# WKUP_CTRL_MMR1_CFG0 register map
Vendor: Texas Instruments
Registers are 32-bit, read-write, reset 0x0 unless marked. A register's access mark holds for its fields unless they carry their own. Offsets are as the file gives them; [hi:lo] are bit positions; {n}, {i} and the like mark numbered series.

## WKUP_CTRL_MMR1_CFG0 (part 2 of 2)
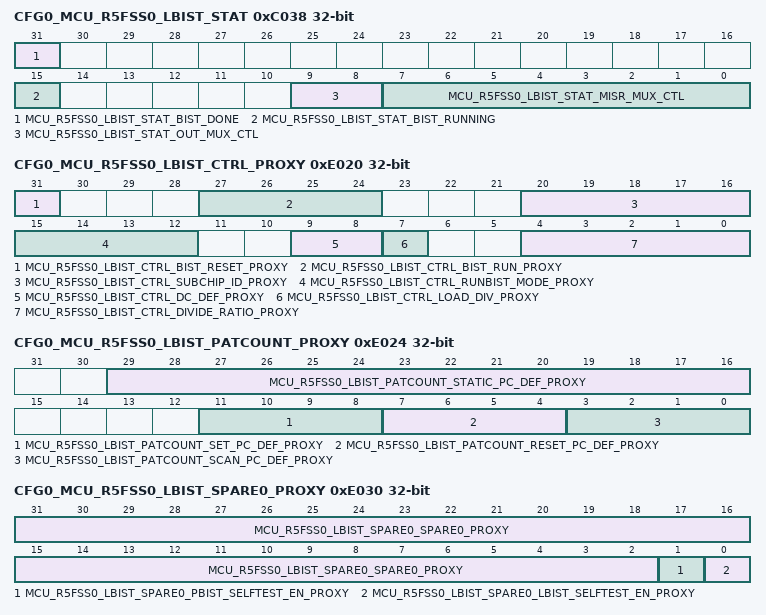
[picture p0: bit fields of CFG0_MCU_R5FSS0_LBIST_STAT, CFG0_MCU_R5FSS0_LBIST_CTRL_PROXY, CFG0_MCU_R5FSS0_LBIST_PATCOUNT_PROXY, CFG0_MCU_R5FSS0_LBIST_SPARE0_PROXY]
0xC038 CFG0_MCU_R5FSS0_LBIST_STAT access per field
  [31] MCU_R5FSS0_LBIST_STAT_BIST_DONE ro — LBIST is done
  [15] MCU_R5FSS0_LBIST_STAT_BIST_RUNNING ro — LBIST is running
  [9:8] MCU_R5FSS0_LBIST_STAT_OUT_MUX_CTL rw — Selects source of LBIST output 00 - LBIST IP PID value 01 - LBIST CTRL ID value 1x - MISR value
  [7:0] MCU_R5FSS0_LBIST_STAT_MISR_MUX_CTL rw — Selects block of 32 MISR bits to read. A value of 0 selects a compacted 32-bit version of the full MISR. A value of 1-32 select a 32-bit segment of the MISR.
0xC03C CFG0_MCU_R5FSS0_LBIST_MISR ro
  [31:0] MCU_R5FSS0_LBIST_MISR_MISR_RESULT — 32-bits of MISR value selected by misr_mux_ctl
0xD100 CFG0_CLAIMREG_P3_R0_READONLY ro
  [31:0] CLAIMREG_P3_R0_READONLY — Claim bits for Partition 3
0xE020 CFG0_MCU_R5FSS0_LBIST_CTRL_PROXY
  [31] MCU_R5FSS0_LBIST_CTRL_BIST_RESET_PROXY — This bitfield is not used.
  [27:24] MCU_R5FSS0_LBIST_CTRL_BIST_RUN_PROXY — This bitfield is not used.
  [20:16] MCU_R5FSS0_LBIST_CTRL_SUBCHIP_ID_PROXY — Specifies which sub-chip is to be tested
  [15:12] MCU_R5FSS0_LBIST_CTRL_RUNBIST_MODE_PROXY — Runbist mode activate if all bits are 1
  [9:8] MCU_R5FSS0_LBIST_CTRL_DC_DEF_PROXY — Clock delay after scan_activate switching
  [7] MCU_R5FSS0_LBIST_CTRL_LOAD_DIV_PROXY — Loads LBIST clock divide ratio on transition from 0 to 1
  [4:0] MCU_R5FSS0_LBIST_CTRL_DIVIDE_RATIO_PROXY — LBIST clock divide ratio
0xE024 CFG0_MCU_R5FSS0_LBIST_PATCOUNT_PROXY
  [29:16] MCU_R5FSS0_LBIST_PATCOUNT_STATIC_PC_DEF_PROXY — Number of stuck-at patterns to run
  [11:8] MCU_R5FSS0_LBIST_PATCOUNT_SET_PC_DEF_PROXY — Number of set patterns to run
  [7:4] MCU_R5FSS0_LBIST_PATCOUNT_RESET_PC_DEF_PROXY — Number of reset patterns to run
  [3:0] MCU_R5FSS0_LBIST_PATCOUNT_SCAN_PC_DEF_PROXY — Number of chain test patterns to run
0xE028 CFG0_MCU_R5FSS0_LBIST_SEED0_PROXY
  [31:0] MCU_R5FSS0_LBIST_SEED0_PRPG_DEF_PROXY — Initial seed for PRPG (bits 31:0)
0xE02C CFG0_MCU_R5FSS0_LBIST_SEED1_PROXY
  [20:0] MCU_R5FSS0_LBIST_SEED1_PRPG_DEF_PROXY — Initial seed for PRPG (bits 52:32)
0xE030 CFG0_MCU_R5FSS0_LBIST_SPARE0_PROXY
  [31:2] MCU_R5FSS0_LBIST_SPARE0_SPARE0_PROXY — LBIST spare bits
  [1] MCU_R5FSS0_LBIST_SPARE0_PBIST_SELFTEST_EN_PROXY — PBIST isolation control
  [0] MCU_R5FSS0_LBIST_SPARE0_LBIST_SELFTEST_EN_PROXY — LBIST isolation control
0xE034 CFG0_MCU_R5FSS0_LBIST_SPARE1_PROXY
  [31:0] MCU_R5FSS0_LBIST_SPARE1_SPARE1_PROXY — LBIST spare bits
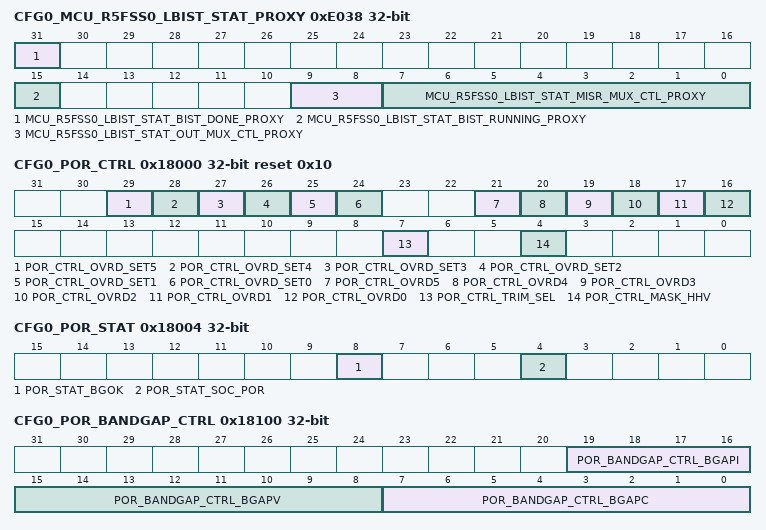
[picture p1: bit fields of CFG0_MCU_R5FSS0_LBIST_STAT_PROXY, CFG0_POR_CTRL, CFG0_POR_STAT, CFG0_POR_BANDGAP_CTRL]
0xE038 CFG0_MCU_R5FSS0_LBIST_STAT_PROXY access per field
  [31] MCU_R5FSS0_LBIST_STAT_BIST_DONE_PROXY ro — LBIST is done
  [15] MCU_R5FSS0_LBIST_STAT_BIST_RUNNING_PROXY ro — LBIST is running
  [9:8] MCU_R5FSS0_LBIST_STAT_OUT_MUX_CTL_PROXY rw — Selects source of LBIST output 00 - LBIST IP PID value 01 - LBIST CTRL ID value 1x - MISR value
  [7:0] MCU_R5FSS0_LBIST_STAT_MISR_MUX_CTL_PROXY rw — Selects block of 32 MISR bits to read. A value of 0 selects a compacted 32-bit version of the full MISR. A value of 1-32 select a 32-bit segment of the MISR.
0xE03C CFG0_MCU_R5FSS0_LBIST_MISR_PROXY ro
  [31:0] MCU_R5FSS0_LBIST_MISR_MISR_RESULT_PROXY — 32-bits of MISR value selected by misr_mux_ctl
0xF100 CFG0_CLAIMREG_P3_R0
  [31:0] CLAIMREG_P3_R0 — Claim bits for Partition 3
{0x11100+4i} CFG0_CLAIMREG_P4_R{i}_READONLY ro (i=0..19)
  [31:0] CLAIMREG_P4_R{i}_READONLY — Claim bits for Partition 4
{0x13100+4i} CFG0_CLAIMREG_P4_R{i} (i=0..19)
  [31:0] CLAIMREG_P4_R{i} — Claim bits for Partition 4
0x18000 CFG0_POR_CTRL reset 0x10
  [29] POR_CTRL_OVRD_SET5 — Reserved override set
  [28] POR_CTRL_OVRD_SET4 — POKLVB override set
  [27] POR_CTRL_OVRD_SET3 — POKLVA override set
  [26] POR_CTRL_OVRD_SET2 — POKHV override set
  [25] POR_CTRL_OVRD_SET1 — BGOK override set
  [24] POR_CTRL_OVRD_SET0 — PORHV override set
  [21] POR_CTRL_OVRD5 — Reserved override activate
  [20] POR_CTRL_OVRD4 — POKLVB override activate
  [19] POR_CTRL_OVRD3 — POKLVA override activate
  [18] POR_CTRL_OVRD2 — POKHV override activate
  [17] POR_CTRL_OVRD1 — BGOK override activate
  [16] POR_CTRL_OVRD0 — PORHV override activate
  [7] POR_CTRL_TRIM_SEL — POR Trim Select 0 - Trim selections for Bandgap and POKs come from HHV defaults 1 - Trim selections for Bandgap and POKs come from POR_BANDGAP_CTRL and POR_POKxxx_CTRL registers
  [4] POR_CTRL_MASK_HHV — Mask HHV/SOC_PORz outputs when applying new trim values
0x18004 CFG0_POR_STAT ro
  [8] POR_STAT_BGOK — Bandgap OK status
  [4] POR_STAT_SOC_POR — POR module status 0 - Module is in functional mode 1 - Module is in reset mode
0x18100 CFG0_POR_BANDGAP_CTRL
  [19:16] POR_BANDGAP_CTRL_BGAPI — Bandgap output current trim bits
  [15:8] POR_BANDGAP_CTRL_BGAPV — Bandgap output voltage magnitude trim bits
  [7:0] POR_BANDGAP_CTRL_BGAPC — Bandgap slope trim bits. Bit7 is used to calculate the offset
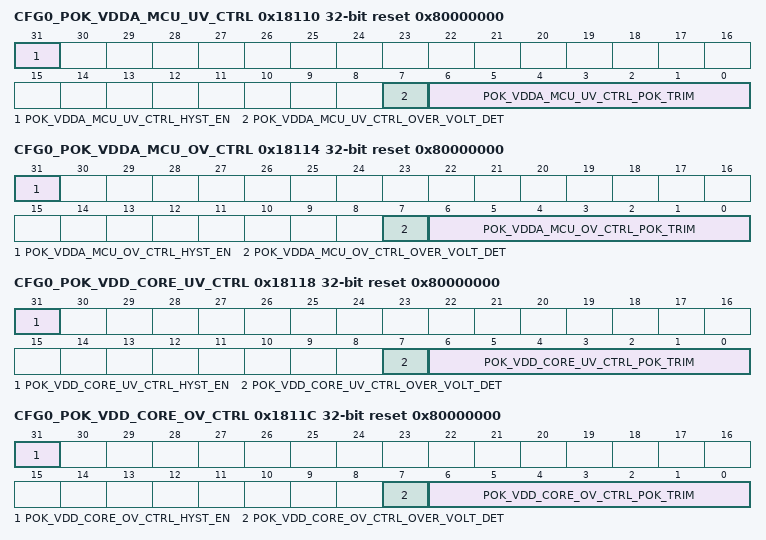
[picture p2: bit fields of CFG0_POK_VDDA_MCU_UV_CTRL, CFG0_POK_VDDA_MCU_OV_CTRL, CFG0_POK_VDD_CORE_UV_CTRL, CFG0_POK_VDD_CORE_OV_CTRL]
0x18110 CFG0_POK_VDDA_MCU_UV_CTRL reset 0x80000000
  [31] POK_VDDA_MCU_UV_CTRL_HYST_EN — Activate POK hysteresis
  [7] POK_VDDA_MCU_UV_CTRL_OVER_VOLT_DET — Over / under voltage detection mode 0 - Under voltage detection 1 - Over voltage detection
  [6:0] POK_VDDA_MCU_UV_CTRL_POK_TRIM — POK Trim Bits
0x18114 CFG0_POK_VDDA_MCU_OV_CTRL reset 0x80000000
  [31] POK_VDDA_MCU_OV_CTRL_HYST_EN — Activate POK hysteresis
  [7] POK_VDDA_MCU_OV_CTRL_OVER_VOLT_DET — Over / under voltage detection mode 0 - Under voltage detection 1 - Over voltage detection
  [6:0] POK_VDDA_MCU_OV_CTRL_POK_TRIM — POK Trim Bits
0x18118 CFG0_POK_VDD_CORE_UV_CTRL reset 0x80000000
  [31] POK_VDD_CORE_UV_CTRL_HYST_EN — Activate POK hysteresis
  [7] POK_VDD_CORE_UV_CTRL_OVER_VOLT_DET — Over / under voltage detection mode 0 - Under voltage detection 1 - Over voltage detection
  [6:0] POK_VDD_CORE_UV_CTRL_POK_TRIM — POK Trim Bits
0x1811C CFG0_POK_VDD_CORE_OV_CTRL reset 0x80000000
  [31] POK_VDD_CORE_OV_CTRL_HYST_EN — Activate POK hysteresis
  [7] POK_VDD_CORE_OV_CTRL_OVER_VOLT_DET — Over / under voltage detection mode 0 - Under voltage detection 1 - Over voltage detection
  [6:0] POK_VDD_CORE_OV_CTRL_POK_TRIM — POK Trim Bits
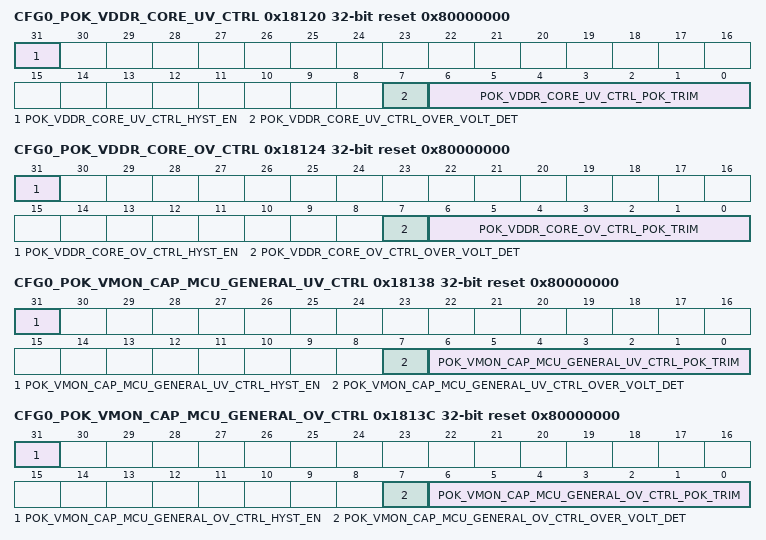
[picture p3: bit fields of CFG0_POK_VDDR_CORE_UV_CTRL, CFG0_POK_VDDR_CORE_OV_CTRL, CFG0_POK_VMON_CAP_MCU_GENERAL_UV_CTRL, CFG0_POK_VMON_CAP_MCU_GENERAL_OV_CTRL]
0x18120 CFG0_POK_VDDR_CORE_UV_CTRL reset 0x80000000
  [31] POK_VDDR_CORE_UV_CTRL_HYST_EN — Activate POK hysteresis
  [7] POK_VDDR_CORE_UV_CTRL_OVER_VOLT_DET — Over / under voltage detection mode 0 - Under voltage detection 1 - Over voltage detection
  [6:0] POK_VDDR_CORE_UV_CTRL_POK_TRIM — POK Trim Bits
0x18124 CFG0_POK_VDDR_CORE_OV_CTRL reset 0x80000000
  [31] POK_VDDR_CORE_OV_CTRL_HYST_EN — Activate POK hysteresis
  [7] POK_VDDR_CORE_OV_CTRL_OVER_VOLT_DET — Over / under voltage detection mode 0 - Under voltage detection 1 - Over voltage detection
  [6:0] POK_VDDR_CORE_OV_CTRL_POK_TRIM — POK Trim Bits
0x18138 CFG0_POK_VMON_CAP_MCU_GENERAL_UV_CTRL reset 0x80000000
  [31] POK_VMON_CAP_MCU_GENERAL_UV_CTRL_HYST_EN — Activate POK hysteresis
  [7] POK_VMON_CAP_MCU_GENERAL_UV_CTRL_OVER_VOLT_DET — Over / under voltage detection mode 0 - Under voltage detection 1 - Over voltage detection
  [6:0] POK_VMON_CAP_MCU_GENERAL_UV_CTRL_POK_TRIM — POK Trim Bits
0x1813C CFG0_POK_VMON_CAP_MCU_GENERAL_OV_CTRL reset 0x80000000
  [31] POK_VMON_CAP_MCU_GENERAL_OV_CTRL_HYST_EN — Activate POK hysteresis
  [7] POK_VMON_CAP_MCU_GENERAL_OV_CTRL_OVER_VOLT_DET — Over / under voltage detection mode 0 - Under voltage detection 1 - Over voltage detection
  [6:0] POK_VMON_CAP_MCU_GENERAL_OV_CTRL_POK_TRIM — POK Trim Bits
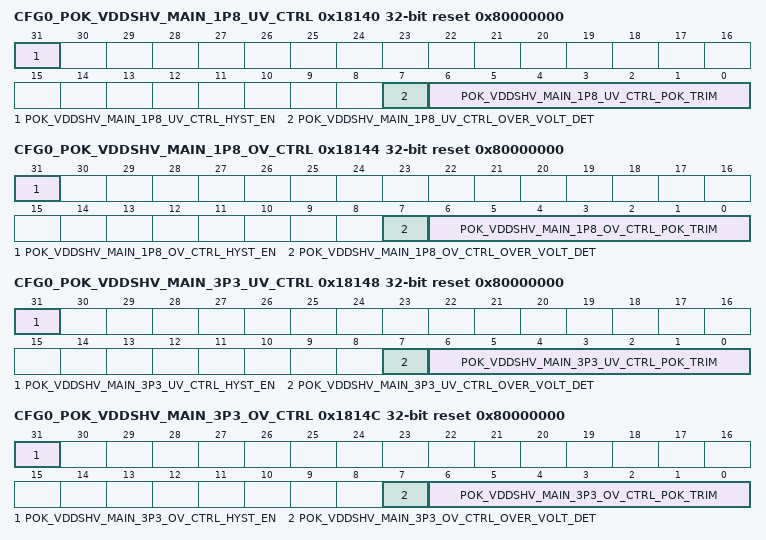
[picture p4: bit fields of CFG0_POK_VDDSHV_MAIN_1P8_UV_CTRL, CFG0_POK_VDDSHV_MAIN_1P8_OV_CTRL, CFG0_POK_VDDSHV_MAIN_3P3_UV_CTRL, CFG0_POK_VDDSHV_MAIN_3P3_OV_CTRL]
0x18140 CFG0_POK_VDDSHV_MAIN_1P8_UV_CTRL reset 0x80000000
  [31] POK_VDDSHV_MAIN_1P8_UV_CTRL_HYST_EN — Activate POK hysteresis
  [7] POK_VDDSHV_MAIN_1P8_UV_CTRL_OVER_VOLT_DET — Over / under voltage detection mode 0 - Under voltage detection 1 - Over voltage detection
  [6:0] POK_VDDSHV_MAIN_1P8_UV_CTRL_POK_TRIM — POK Trim Bits
0x18144 CFG0_POK_VDDSHV_MAIN_1P8_OV_CTRL reset 0x80000000
  [31] POK_VDDSHV_MAIN_1P8_OV_CTRL_HYST_EN — Activate POK hysteresis
  [7] POK_VDDSHV_MAIN_1P8_OV_CTRL_OVER_VOLT_DET — Over / under voltage detection mode 0 - Under voltage detection 1 - Over voltage detection
  [6:0] POK_VDDSHV_MAIN_1P8_OV_CTRL_POK_TRIM — POK Trim Bits
0x18148 CFG0_POK_VDDSHV_MAIN_3P3_UV_CTRL reset 0x80000000
  [31] POK_VDDSHV_MAIN_3P3_UV_CTRL_HYST_EN — Activate POK hysteresis
  [7] POK_VDDSHV_MAIN_3P3_UV_CTRL_OVER_VOLT_DET — Over / under voltage detection mode 0 - Under voltage detection 1 - Over voltage detection
  [6:0] POK_VDDSHV_MAIN_3P3_UV_CTRL_POK_TRIM — POK Trim Bits
0x1814C CFG0_POK_VDDSHV_MAIN_3P3_OV_CTRL reset 0x80000000
  [31] POK_VDDSHV_MAIN_3P3_OV_CTRL_HYST_EN — Activate POK hysteresis
  [7] POK_VDDSHV_MAIN_3P3_OV_CTRL_OVER_VOLT_DET — Over / under voltage detection mode 0 - Under voltage detection 1 - Over voltage detection
  [6:0] POK_VDDSHV_MAIN_3P3_OV_CTRL_POK_TRIM — POK Trim Bits
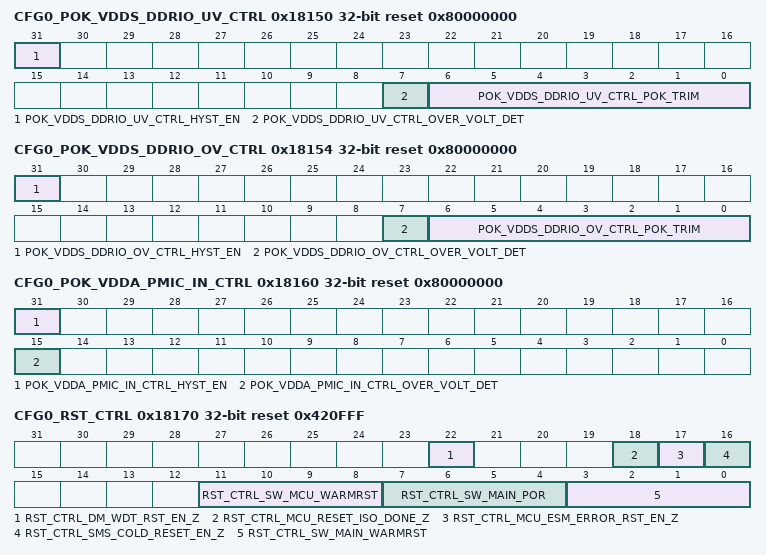
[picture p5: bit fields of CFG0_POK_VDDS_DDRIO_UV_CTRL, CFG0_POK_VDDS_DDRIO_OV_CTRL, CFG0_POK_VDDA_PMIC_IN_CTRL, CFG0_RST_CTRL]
0x18150 CFG0_POK_VDDS_DDRIO_UV_CTRL reset 0x80000000
  [31] POK_VDDS_DDRIO_UV_CTRL_HYST_EN — Activate POK hysteresis
  [7] POK_VDDS_DDRIO_UV_CTRL_OVER_VOLT_DET — Over / under voltage detection mode 0 - Under voltage detection 1 - Over voltage detection
  [6:0] POK_VDDS_DDRIO_UV_CTRL_POK_TRIM — POK Trim Bits
0x18154 CFG0_POK_VDDS_DDRIO_OV_CTRL reset 0x80000000
  [31] POK_VDDS_DDRIO_OV_CTRL_HYST_EN — Activate POK hysteresis
  [7] POK_VDDS_DDRIO_OV_CTRL_OVER_VOLT_DET — Over / under voltage detection mode 0 - Under voltage detection 1 - Over voltage detection
  [6:0] POK_VDDS_DDRIO_OV_CTRL_POK_TRIM — POK Trim Bits
0x18160 CFG0_POK_VDDA_PMIC_IN_CTRL reset 0x80000000
  [31] POK_VDDA_PMIC_IN_CTRL_HYST_EN — Activate POK hysteresis
  [15] POK_VDDA_PMIC_IN_CTRL_OVER_VOLT_DET — Over / under voltage detection mode 0 - Under voltage detection 1 - Over voltage detection
0x18170 CFG0_RST_CTRL reset 0x420FFF
  [22] RST_CTRL_DM_WDT_RST_EN_Z — Deactivate Reset from DM WDT propogating to MCU domain: 0 - Activated 1 - Deactivated
  [18] RST_CTRL_MCU_RESET_ISO_DONE_Z — MCU can set this bit to block warm reset in the main domain which is useful when the MCU may be accessing main domain resources (peripherals, memory..). In this case, the MCU will be notified via an interrupt that there is an outstanding warm reset request for the main domain. Once notified, MCU needs to finish any outstanding operations in has with main domain resources and then clear this bit. After this bit is cleared, the main domain warm reset will unblocked and the warm reset sequence may continue. 0 - Reset of Main Domain is not Blocked by MCU Domain 1 - Reset of Main Domain is Blocked by MCU Domain
  [17] RST_CTRL_MCU_ESM_ERROR_RST_EN_Z — Deactivate Reset of MCU by ESM 0 - Activated 1 - Deactivated
  [16] RST_CTRL_SMS_COLD_RESET_EN_Z — Deactivate Reset of MCU by SMS 0 - Activated 1 - Deactivated
  [11:8] RST_CTRL_SW_MCU_WARMRST — This is a fault tolerant bitfield. Causes MCU Domain Warm Reset when set to 4'b0110, Bits will reset to 4'b1111
  [7:4] RST_CTRL_SW_MAIN_POR — This is a fault tolerant bitfield. Causes MAIN Domain Power On Reset when set to 4'b0110, Bits will reset to 4'b1111
  [3:0] RST_CTRL_SW_MAIN_WARMRST — This is a fault tolerant bitfield. Causes MAIN Domain Warm Reset when set to 4'b0110, Bits will reset to 4'b1111
0x18174 CFG0_RST_STAT ro
  [0] RST_STAT_MAIN_RESETSTATZ — Status of Main Domain Reset: 0 = Reset Asserted 1 = Reset Deasserted
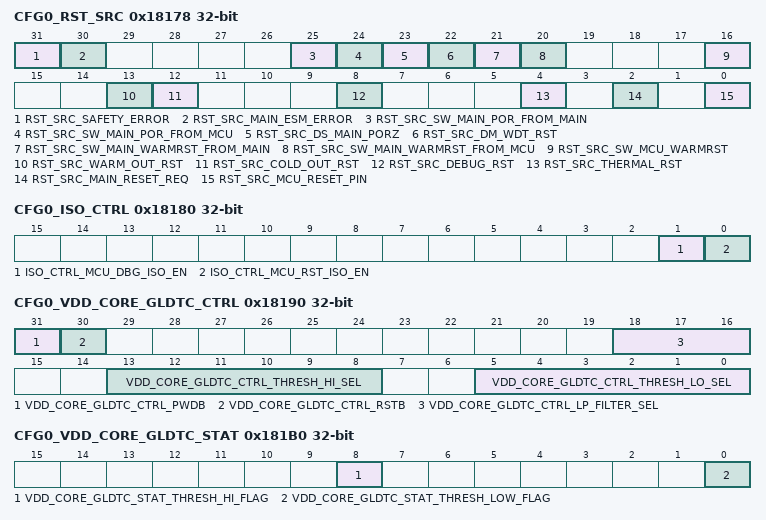
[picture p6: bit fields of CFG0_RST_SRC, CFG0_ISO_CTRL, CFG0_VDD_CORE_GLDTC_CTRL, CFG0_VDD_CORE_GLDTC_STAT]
0x18178 CFG0_RST_SRC access not given
  [31] RST_SRC_SAFETY_ERROR — Reset Caused by MCU ESM Error (access R/W1TC)
  [30] RST_SRC_MAIN_ESM_ERROR — Reset Caused by Main ESM Error (access R/W1TC)
  [25] RST_SRC_SW_MAIN_POR_FROM_MAIN — Software Main Power On Reset From MAIN CTRL MMR (access R/W1TC)
  [24] RST_SRC_SW_MAIN_POR_FROM_MCU — Software Main Power On Reset From MCU CTRL MMR (access R/W1TC)
  [23] RST_SRC_DS_MAIN_PORZ — Reset of Main/Wkup Domains while in Deep Sleep, as a result of an MCU Warm Reset (access R/W1TC)
  [22] RST_SRC_DM_WDT_RST — Watchdog Initiated Reset (access R/W1TC)
  [21] RST_SRC_SW_MAIN_WARMRST_FROM_MAIN — Software Main Warm Reset from MAIN CTRL MMR (access R/W1TC)
  [20] RST_SRC_SW_MAIN_WARMRST_FROM_MCU — Software Main Warm Reset From MCU CTRL MMR (access R/W1TC)
  [16] RST_SRC_SW_MCU_WARMRST — Software Warm Reset (access R/W1TC)
  [13] RST_SRC_WARM_OUT_RST — SMS Warm Reset (access R/W1TC)
  [12] RST_SRC_COLD_OUT_RST — SMS Cold Reset (access R/W1TC)
  [8] RST_SRC_DEBUG_RST — Debug Subsystem Initiated Reset (access R/W1TC)
  [4] RST_SRC_THERMAL_RST — Thermal Reset (access R/W1TC)
  [2] RST_SRC_MAIN_RESET_REQ — Main Reset Pin (access R/W1TC)
  [0] RST_SRC_MCU_RESET_PIN — Rest Caused by MCU Reset Pin (access R/W1TC)
0x1817C CFG0_RST_MAGIC_WORD
  [31:0] RST_MAGIC_WORD_MCU_MAGIC_WORD — After a MCU_PORz reset this bit field resets to 0x00000000. While this bit field remains 0x00000000 any reset from the Main Domain also propagates through the MCU domain. If the application does not require reset isolation of the MCU domain, it shall leave this bit field with a value of 0x00000000. If the application does require reset isolation of the MCU domain after the initial boot, then the MCU R5FSS CPU must write a nonzero value to the magic word. The actual value is left to software and different values may be used to convey information, but in order to isolate the MCU domain from any warm reset sources that triggers main_resetz, the value must be non-zero. If the value is nonzero and a Main domain warm reset that triggers main_resetz occurs in the main domain, the MCU R5FSS will not be reset. The Main domain bootloader must read this value to determine that the MCU R5FSS is already initialized, and has configured reset isolation. The Main domain bootloader then also skips any initialization steps involving bootstrapping the R5FSS (as it is is already running). Note that MCU_PORz reset is never blocked by a nonzero magic word.
0x18180 CFG0_ISO_CTRL
  [1] ISO_CTRL_MCU_DBG_ISO_EN — Isolates the MCU domain from Debug Field values (others are reserved): undefined - undefined undefined - undefined 1'b0 - R5FSS is not debug isolated 1'b1 - R5FSS is isolated from debug if RST_MAGIC_WORD is also nonzero
  [0] ISO_CTRL_MCU_RST_ISO_EN — Isolates the MCU domain from Warm Reset initiated by Main Field values (others are reserved): undefined - undefined undefined - undefined 1'b0 - R5FSS is not reset isolated 1'b1 - R5FSS is isolated from main warm reset if RST_MAGIC_WORD is also nonzero
0x18190 CFG0_VDD_CORE_GLDTC_CTRL
  [31] VDD_CORE_GLDTC_CTRL_PWDB — Power down - active low. 0 - Deactivate all functions 1 - Activate glitch detectors
  [30] VDD_CORE_GLDTC_CTRL_RSTB — Reset - active low. To ensure proper operation, rstb must be not be de-asserted for at least 100 ns after power-up (pwdb de-asserted). Additionally, rstb must be toggled low at least 200 ns after any change in threshold or low-pass filter settings to prevent abnormal trigger events. 0 - Reset glitch detector flags 1 - Glitch detection flags are activated
  [18:16] VDD_CORE_GLDTC_CTRL_LP_FILTER_SEL — Selects the glitch detect low-pass filter bandwidth Field values (others are reserved): 3'b000 - 150 kHz 3'b001 - 125 kHz 3'b010 - 100 kHz 3'b011 - 80 kHz 3'b100 - 60 kHz 3'b101 - 45 kHz 3'b110 - 30 kHz 3'b111 - 15 kHz
  [13:8] VDD_CORE_GLDTC_CTRL_THRESH_HI_SEL — Selects the high voltage glitch threshold as a percentage of the monitored voltage Field values (others are reserved): 6'b000000 - 93.5% of VDD 6'b000001 - 94.0% of VDD 6'b000010 - 94.5% of VDD 6'b000011 - 95.0% of VDD 6'b000100 - 95.5% of VDD 6'b000101 - 96.0% of VDD 6'b000110 - 96.5% of VDD 6'b000111 - 97.0% of VDD 6'b001000 - 97.5% of VDD 6'b001001 - 98.0% of VDD 6'b001010 - 98.5% of VDD 6'b001011 - 99.0% of VDD 6'b001100 - 99.5% of VDD 6'b001101 - 100.0% of VDD 6'b001110 - 100.5% of VDD 6'b001111 - 101.0% of VDD 6'b010000 - 101.5% of VDD 6'b010001 - 102.0% of VDD 6'b010010 - 102.5% of VDD 6'b010011 - 103.0% of VDD 6'b010100 - 103.5% of VDD 6'b010101 - 104.0% of VDD 6'b010110 - 104.5% of VDD 6'b010111 - 105.0% of VDD 6'b011000 - 105.5% of VDD 6'b011001 - 106.0% of VDD 6'b011010 - 106.5% of VDD 6'b011011 - 107.0% of VDD 6'b011100 - 107.5% of VDD 6'b011101 - 108.0% of VDD 6'b011110 - 108.5% of VDD 6'b011111 - 109.0% of VDD 6'b100000 - 109.5% of VDD 6'b100001 - 110.0% of VDD 6'b100010 - 111.0% of VDD 6'b100011 - 112.0% of VDD 6'b100100 - 113.0% of VDD 6'b100101 - 114.0% of VDD 6'b100110 - 115.0% of VDD 6'b100111 - 116.0% of VDD 6'b101000 - 117.0% of VDD 6'b101001 - 118.0% of VDD 6'b101010 - 119.0% of VDD 6'b101011 - 120.0% of VDD 6'b101100 - 121.0% of VDD 6'b101101 - 122.0% of VDD 6'b101110 - 123.0% of VDD 6'b101111 - 124.0% of VDD 6'b110000 - 125.0% of VDD 6'b110001 - 126.0% of VDD 6'b110010 - 127.0% of VDD 6'b110011 - 128.0% of VDD 6'b110100 - 129.0% of VDD 6'b110101 - 130.0% of VDD 6'b110110 - 131.0% of VDD 6'b110111 - 132.0% of VDD 6'b111000 - 133.0% of VDD 6'b111001 - 134.0% of VDD 6'b111010 - 135.0% of VDD 6'b111011 - 136.0% of VDD 6'b111100 - 137.0% of VDD 6'b111101 - 138.0% of VDD 6'b111110 - 139.0% of VDD 6'b111111 - 140.0% of VDD
  [5:0] VDD_CORE_GLDTC_CTRL_THRESH_LO_SEL — Selects the low voltage glitch threshold as a percentage of the monitored voltage Field values (others are reserved): 6'b000000 - 106.5% of VDD 6'b000001 - 106.0% of VDD 6'b000010 - 105.5% of VDD 6'b000011 - 105.0% of VDD 6'b000100 - 104.5% of VDD 6'b000101 - 104.0% of VDD 6'b000110 - 103.5% of VDD 6'b000111 - 103.0% of VDD 6'b001000 - 102.5% of VDD 6'b001001 - 102.0% of VDD 6'b001010 - 101.5% of VDD 6'b001011 - 101.0% of VDD 6'b001100 - 100.5% of VDD 6'b001101 - 100.0% of VDD 6'b001110 - 99.5% of VDD 6'b001111 - 99.0% of VDD 6'b010000 - 98.5% of VDD 6'b010001 - 98.0% of VDD 6'b010010 - 97.5% of VDD 6'b010011 - 97.0% of VDD 6'b010100 - 96.5% of VDD 6'b010101 - 96.0% of VDD 6'b010110 - 95.5% of VDD 6'b010111 - 95.0% of VDD 6'b011000 - 94.5% of VDD 6'b011001 - 94.0% of VDD 6'b011010 - 93.5% of VDD 6'b011011 - 93.0% of VDD 6'b011100 - 92.5% of VDD 6'b011101 - 92.0% of VDD 6'b011110 - 91.5% of VDD 6'b011111 - 91.0% of VDD 6'b100000 - 90.5% of VDD 6'b100001 - 90.0% of VDD 6'b100010 - 89.0% of VDD 6'b100011 - 88.0% of VDD 6'b100100 - 87.0% of VDD 6'b100101 - 86.0% of VDD 6'b100110 - 85.0% of VDD 6'b100111 - 84.0% of VDD 6'b101000 - 83.0% of VDD 6'b101001 - 82.0% of VDD 6'b101010 - 81.0% of VDD 6'b101011 - 80.0% of VDD 6'b101100 - 79.0% of VDD 6'b101101 - 78.0% of VDD 6'b101110 - 77.0% of VDD 6'b101111 - 76.0% of VDD 6'b110000 - 75.0% of VDD 6'b110001 - 74.0% of VDD 6'b110010 - 73.0% of VDD 6'b110011 - 72.0% of VDD 6'b110100 - 71.0% of VDD 6'b110101 - 70.0% of VDD 6'b110110 - 69.0% of VDD 6'b110111 - 68.0% of VDD 6'b111000 - 67.0% of VDD 6'b111001 - 66.0% of VDD 6'b111010 - 65.0% of VDD 6'b111011 - 64.0% of VDD 6'b111100 - 63.0% of VDD 6'b111101 - 62.0% of VDD 6'b111110 - 61.0% of VDD 6'b111111 - 60.0% of VDD
0x181B0 CFG0_VDD_CORE_GLDTC_STAT ro
  [8] VDD_CORE_GLDTC_STAT_THRESH_HI_FLAG — High voltage flag. This flag is cleared by clearing the VDD_CORE_GLDTC_CTRL_rstb bit. 0 - No high voltage detected 1 - Voltage above the high voltage threshold was detected.
  [0] VDD_CORE_GLDTC_STAT_THRESH_LOW_FLAG — Low voltage flag. This flag is cleared by clearing the VDD_CORE_GLDTC_CTRL_rstb bit. 0 - No low voltage detected 1 - Voltage below the low voltage threshold was detected.
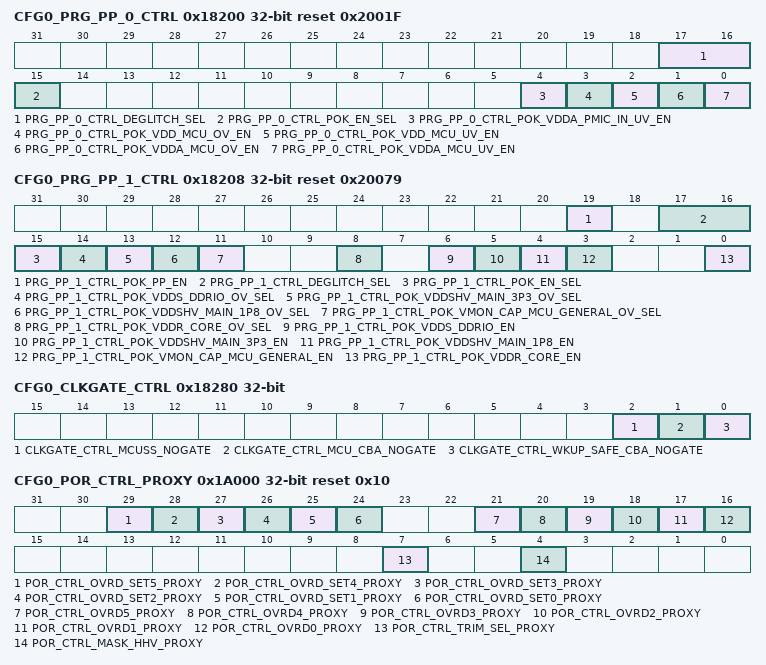
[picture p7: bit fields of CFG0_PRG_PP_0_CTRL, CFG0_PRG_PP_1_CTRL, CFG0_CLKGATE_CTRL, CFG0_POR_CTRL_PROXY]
0x18200 CFG0_PRG_PP_0_CTRL reset 0x2001F
  [17:16] PRG_PP_0_CTRL_DEGLITCH_SEL — Deglitch period for PRG_PP0 POKs: 2'b00 - 5 us 2'b01 -10 us 2'b10 - 15 us 2'b11 - 20us
  [15] PRG_PP_0_CTRL_POK_EN_SEL — Select POK activate source 0 - POK activates come from hardware tie-offs 1 - POK activates come from PRG_PP0_CTRL register
  [4] PRG_PP_0_CTRL_POK_VDDA_PMIC_IN_UV_EN — Activate VDDA_PMIC_IN undervoltage POK detection 0 - POK detection deactivated 1 - POK detection activated
  [3] PRG_PP_0_CTRL_POK_VDD_MCU_OV_EN — Activate VDD_MCU overvoltage POK detection 0 - POK detection deactivated 1 - POK detection activated
  [2] PRG_PP_0_CTRL_POK_VDD_MCU_UV_EN — Activate VDD_MCU undervoltage POK detection 0 - POK detection deactivated 1 - POK detection activated
  [1] PRG_PP_0_CTRL_POK_VDDA_MCU_OV_EN — Activate 1.8V VDDA_MCU overvoltage POK detection 0 - POK detection deactivated 1 - POK detection activated
  [0] PRG_PP_0_CTRL_POK_VDDA_MCU_UV_EN — Activate 1.8V VDDA_MCU undervoltage POK detection 0 - POK detection deactivated 1 - POK detection activated
0x18208 CFG0_PRG_PP_1_CTRL reset 0x20079
  [19] PRG_PP_1_CTRL_POK_PP_EN — POK ping-pong activate. When set, activatesautomatic switching between undervoltage andovervoltage detection on PRG_PP1 (POK_VDDR_CORE, POK_VDDSHV_MCU_1P8, POK_VDDSHV_MCU_3P3, POK_VMON_CAP_MCU_GENERAL, POK_VDDSHV_MAIN_1P8, POK_VDDSHV_MAIN_3P3, and POK_VDDS_DDRIO) POKs. This bit has no effect if the POK's ov_sel bit = 1. 0 - No pingpong operation. UV/OV operationselected by each POK ov_sel bit 1 - Pingpong operation activated .
  [17:16] PRG_PP_1_CTRL_DEGLITCH_SEL — Deglitch period for PRG_PP1 POKs: 2'b00 - 5 us 2'b01 -10 us 2'b10 - 15 us 2'b11 - 20us
  [15] PRG_PP_1_CTRL_POK_EN_SEL — Select POK activate source 0 - POK activates come from hardware tie-offs 1 - POK activates come from PRG_PP1_CTRL register
  [14] PRG_PP_1_CTRL_POK_VDDS_DDRIO_OV_SEL — POK_VDDS_DDRIO mode: 0 = Undervoltage (pok_pp_en = 0) Ping-Pong (pok_pp_en = 1) 1 = Overvoltage (pok_pp_en = x)
  [13] PRG_PP_1_CTRL_POK_VDDSHV_MAIN_3P3_OV_SEL — POK_VDDSHV_MAIN_3P3 mode: 0 = Undervoltage (pok_pp_en = 0) Ping-Pong (pok_pp_en = 1) 1 = Overvoltage (pok_pp_en = x)
  [12] PRG_PP_1_CTRL_POK_VDDSHV_MAIN_1P8_OV_SEL — POK_VDDSHV_MAIN_1P8 mode: 0 = Undervoltage (pok_pp_en = 0) Ping-Pong (pok_pp_en = 1) 1 = Overvoltage (pok_pp_en = x)
  [11] PRG_PP_1_CTRL_POK_VMON_CAP_MCU_GENERAL_OV_SEL — POK_VMON_CAP_MCU_GENERAL mode: 0 = Undervoltage (pok_pp_en = 0) Ping-Pong (pok_pp_en = 1) 1 = Overvoltage (pok_pp_en = x)
  [8] PRG_PP_1_CTRL_POK_VDDR_CORE_OV_SEL — POK_VDDR_CORE Mode: 0 = Undervoltage (pok_pp_en = 0) Ping-Pong (pok_pp_en = 1) 1 = Overvoltage (pok_pp_en = x)
  [6] PRG_PP_1_CTRL_POK_VDDS_DDRIO_EN — Activate POK_VDDS_DDRIO (if pok_en_sel = 1): 0 = POK Detection Deactivated 1 = POK Detection Activated
  [5] PRG_PP_1_CTRL_POK_VDDSHV_MAIN_3P3_EN — Activate POK_VDDSHV_MAIN_3P3 (if pok_en_sel = 1): 0 = POK Detection Deactivated 1 = POK Detection Activated
  [4] PRG_PP_1_CTRL_POK_VDDSHV_MAIN_1P8_EN — Activate POK_VDDSHV_MAIN_1P8 (if pok_en_sel = 1): 0 = POK Detection Deactivated 1 = POK Detection Activated
  [3] PRG_PP_1_CTRL_POK_VMON_CAP_MCU_GENERAL_EN — Activate POK_VMON_CAP_MCU_GENERAL (if pok_en_sel = 1): 0 = POK Detection Deactivated 1 = POK Detection Activated
  [0] PRG_PP_1_CTRL_POK_VDDR_CORE_EN — Activate POK_VDDR_CORE (if pok_en_sel = 1): 0 = POK Detection Deactivated 1 = POK Detection Activated
0x18280 CFG0_CLKGATE_CTRL
  [2] CLKGATE_CTRL_MCUSS_NOGATE — MCU Subsystem clock gate deactivate. 0 - Clocks are gated on idle for power savings 1 - Clocks are not gated on idle, power saving deactivated
  [1] CLKGATE_CTRL_MCU_CBA_NOGATE — MCU domain Data bus (mcu_cbass) clock gate deactivate. 0 - Clocks are gated on idle for power savings 1 - Clocks are not gated on idle, power saving deactivated
  [0] CLKGATE_CTRL_WKUP_SAFE_CBA_NOGATE — WKUP domain Infrastructure bus (wkup_safe_cbass) clock gate deactivate. 0 - Clocks are gated on idle for power savings 1 - Clocks are not gated on idle, power saving deactivated
0x19008 CFG0_LOCK6_KICK0
  [31:0] LOCK6_KICK0 — - KICK0 component
0x1900C CFG0_LOCK6_KICK1
  [31:0] LOCK6_KICK1 — - KICK1 component
{0x19100+4i} CFG0_CLAIMREG_P6_R{i}_READONLY ro (i=0..5)
  [31:0] CLAIMREG_P6_R{i}_READONLY — Claim bits for Partition 6
0x1A000 CFG0_POR_CTRL_PROXY reset 0x10
  [29] POR_CTRL_OVRD_SET5_PROXY — Reserved override set
  [28] POR_CTRL_OVRD_SET4_PROXY — POKLVB override set
  [27] POR_CTRL_OVRD_SET3_PROXY — POKLVA override set
  [26] POR_CTRL_OVRD_SET2_PROXY — POKHV override set
  [25] POR_CTRL_OVRD_SET1_PROXY — BGOK override set
  [24] POR_CTRL_OVRD_SET0_PROXY — PORHV override set
  [21] POR_CTRL_OVRD5_PROXY — Reserved override activate
  [20] POR_CTRL_OVRD4_PROXY — POKLVB override activate
  [19] POR_CTRL_OVRD3_PROXY — POKLVA override activate
  [18] POR_CTRL_OVRD2_PROXY — POKHV override activate
  [17] POR_CTRL_OVRD1_PROXY — BGOK override activate
  [16] POR_CTRL_OVRD0_PROXY — PORHV override activate
  [7] POR_CTRL_TRIM_SEL_PROXY — POR Trim Select 0 - Trim selections for Bandgap and POKs come from HHV defaults 1 - Trim selections for Bandgap and POKs come from POR_BANDGAP_CTRL and POR_POKxxx_CTRL registers
  [4] POR_CTRL_MASK_HHV_PROXY — Mask HHV/SOC_PORz outputs when applying new trim values
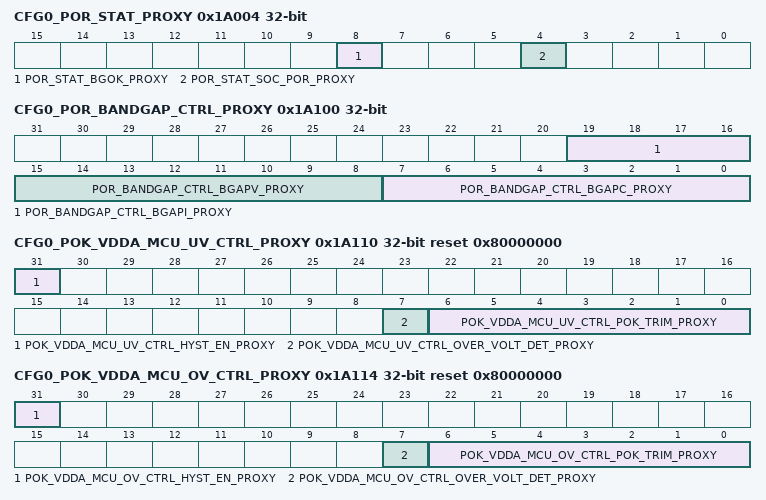
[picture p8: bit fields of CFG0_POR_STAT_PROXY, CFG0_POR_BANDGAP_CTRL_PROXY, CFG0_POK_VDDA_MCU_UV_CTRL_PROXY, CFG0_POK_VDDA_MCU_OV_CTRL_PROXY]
0x1A004 CFG0_POR_STAT_PROXY ro
  [8] POR_STAT_BGOK_PROXY — Bandgap OK status
  [4] POR_STAT_SOC_POR_PROXY — POR module status 0 - Module is in functional mode 1 - Module is in reset mode
0x1A100 CFG0_POR_BANDGAP_CTRL_PROXY
  [19:16] POR_BANDGAP_CTRL_BGAPI_PROXY — Bandgap output current trim bits
  [15:8] POR_BANDGAP_CTRL_BGAPV_PROXY — Bandgap output voltage magnitude trim bits
  [7:0] POR_BANDGAP_CTRL_BGAPC_PROXY — Bandgap slope trim bits. Bit7 is used to calculate the offset
0x1A110 CFG0_POK_VDDA_MCU_UV_CTRL_PROXY reset 0x80000000
  [31] POK_VDDA_MCU_UV_CTRL_HYST_EN_PROXY — Activate POK hysteresis
  [7] POK_VDDA_MCU_UV_CTRL_OVER_VOLT_DET_PROXY — Over / under voltage detection mode 0 - Under voltage detection 1 - Over voltage detection
  [6:0] POK_VDDA_MCU_UV_CTRL_POK_TRIM_PROXY — POK Trim Bits
0x1A114 CFG0_POK_VDDA_MCU_OV_CTRL_PROXY reset 0x80000000
  [31] POK_VDDA_MCU_OV_CTRL_HYST_EN_PROXY — Activate POK hysteresis
  [7] POK_VDDA_MCU_OV_CTRL_OVER_VOLT_DET_PROXY — Over / under voltage detection mode 0 - Under voltage detection 1 - Over voltage detection
  [6:0] POK_VDDA_MCU_OV_CTRL_POK_TRIM_PROXY — POK Trim Bits
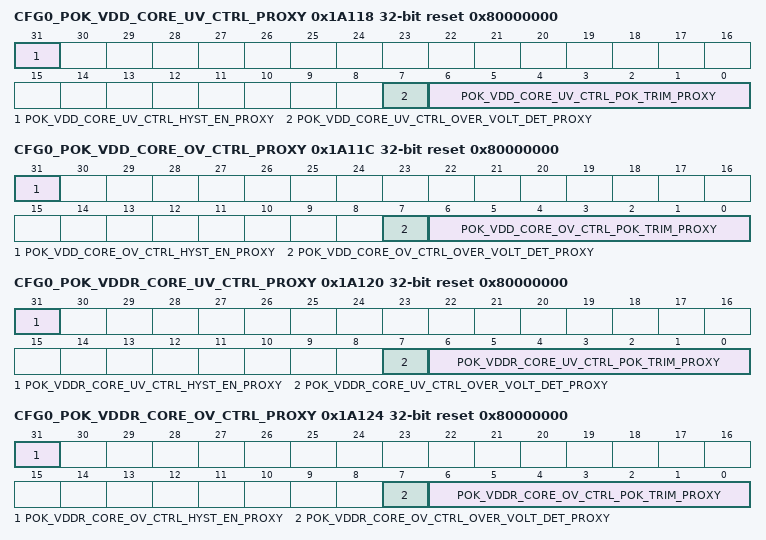
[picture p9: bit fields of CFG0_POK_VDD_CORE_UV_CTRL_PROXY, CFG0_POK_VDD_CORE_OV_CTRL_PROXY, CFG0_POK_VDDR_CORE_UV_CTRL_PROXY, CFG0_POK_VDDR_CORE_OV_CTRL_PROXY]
0x1A118 CFG0_POK_VDD_CORE_UV_CTRL_PROXY reset 0x80000000
  [31] POK_VDD_CORE_UV_CTRL_HYST_EN_PROXY — Activate POK hysteresis
  [7] POK_VDD_CORE_UV_CTRL_OVER_VOLT_DET_PROXY — Over / under voltage detection mode 0 - Under voltage detection 1 - Over voltage detection
  [6:0] POK_VDD_CORE_UV_CTRL_POK_TRIM_PROXY — POK Trim Bits
0x1A11C CFG0_POK_VDD_CORE_OV_CTRL_PROXY reset 0x80000000
  [31] POK_VDD_CORE_OV_CTRL_HYST_EN_PROXY — Activate POK hysteresis
  [7] POK_VDD_CORE_OV_CTRL_OVER_VOLT_DET_PROXY — Over / under voltage detection mode 0 - Under voltage detection 1 - Over voltage detection
  [6:0] POK_VDD_CORE_OV_CTRL_POK_TRIM_PROXY — POK Trim Bits
0x1A120 CFG0_POK_VDDR_CORE_UV_CTRL_PROXY reset 0x80000000
  [31] POK_VDDR_CORE_UV_CTRL_HYST_EN_PROXY — Activate POK hysteresis
  [7] POK_VDDR_CORE_UV_CTRL_OVER_VOLT_DET_PROXY — Over / under voltage detection mode 0 - Under voltage detection 1 - Over voltage detection
  [6:0] POK_VDDR_CORE_UV_CTRL_POK_TRIM_PROXY — POK Trim Bits
0x1A124 CFG0_POK_VDDR_CORE_OV_CTRL_PROXY reset 0x80000000
  [31] POK_VDDR_CORE_OV_CTRL_HYST_EN_PROXY — Activate POK hysteresis
  [7] POK_VDDR_CORE_OV_CTRL_OVER_VOLT_DET_PROXY — Over / under voltage detection mode 0 - Under voltage detection 1 - Over voltage detection
  [6:0] POK_VDDR_CORE_OV_CTRL_POK_TRIM_PROXY — POK Trim Bits
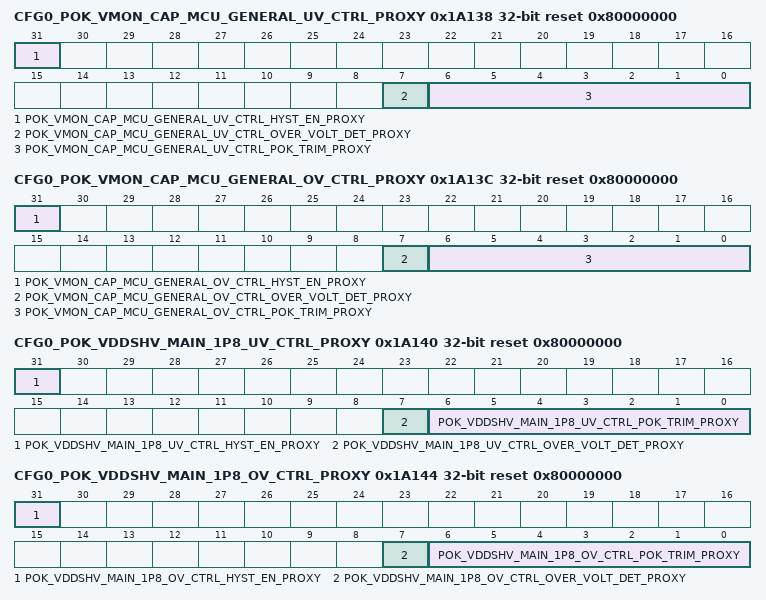
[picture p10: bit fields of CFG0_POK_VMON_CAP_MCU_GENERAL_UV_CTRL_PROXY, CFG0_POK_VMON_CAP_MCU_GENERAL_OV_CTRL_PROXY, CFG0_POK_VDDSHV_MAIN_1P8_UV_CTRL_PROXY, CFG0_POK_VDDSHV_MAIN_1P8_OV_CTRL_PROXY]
0x1A138 CFG0_POK_VMON_CAP_MCU_GENERAL_UV_CTRL_PROXY reset 0x80000000
  [31] POK_VMON_CAP_MCU_GENERAL_UV_CTRL_HYST_EN_PROXY — Activate POK hysteresis
  [7] POK_VMON_CAP_MCU_GENERAL_UV_CTRL_OVER_VOLT_DET_PROXY — Over / under voltage detection mode 0 - Under voltage detection 1 - Over voltage detection
  [6:0] POK_VMON_CAP_MCU_GENERAL_UV_CTRL_POK_TRIM_PROXY — POK Trim Bits
0x1A13C CFG0_POK_VMON_CAP_MCU_GENERAL_OV_CTRL_PROXY reset 0x80000000
  [31] POK_VMON_CAP_MCU_GENERAL_OV_CTRL_HYST_EN_PROXY — Activate POK hysteresis
  [7] POK_VMON_CAP_MCU_GENERAL_OV_CTRL_OVER_VOLT_DET_PROXY — Over / under voltage detection mode 0 - Under voltage detection 1 - Over voltage detection
  [6:0] POK_VMON_CAP_MCU_GENERAL_OV_CTRL_POK_TRIM_PROXY — POK Trim Bits
0x1A140 CFG0_POK_VDDSHV_MAIN_1P8_UV_CTRL_PROXY reset 0x80000000
  [31] POK_VDDSHV_MAIN_1P8_UV_CTRL_HYST_EN_PROXY — Activate POK hysteresis
  [7] POK_VDDSHV_MAIN_1P8_UV_CTRL_OVER_VOLT_DET_PROXY — Over / under voltage detection mode 0 - Under voltage detection 1 - Over voltage detection
  [6:0] POK_VDDSHV_MAIN_1P8_UV_CTRL_POK_TRIM_PROXY — POK Trim Bits
0x1A144 CFG0_POK_VDDSHV_MAIN_1P8_OV_CTRL_PROXY reset 0x80000000
  [31] POK_VDDSHV_MAIN_1P8_OV_CTRL_HYST_EN_PROXY — Activate POK hysteresis
  [7] POK_VDDSHV_MAIN_1P8_OV_CTRL_OVER_VOLT_DET_PROXY — Over / under voltage detection mode 0 - Under voltage detection 1 - Over voltage detection
  [6:0] POK_VDDSHV_MAIN_1P8_OV_CTRL_POK_TRIM_PROXY — POK Trim Bits
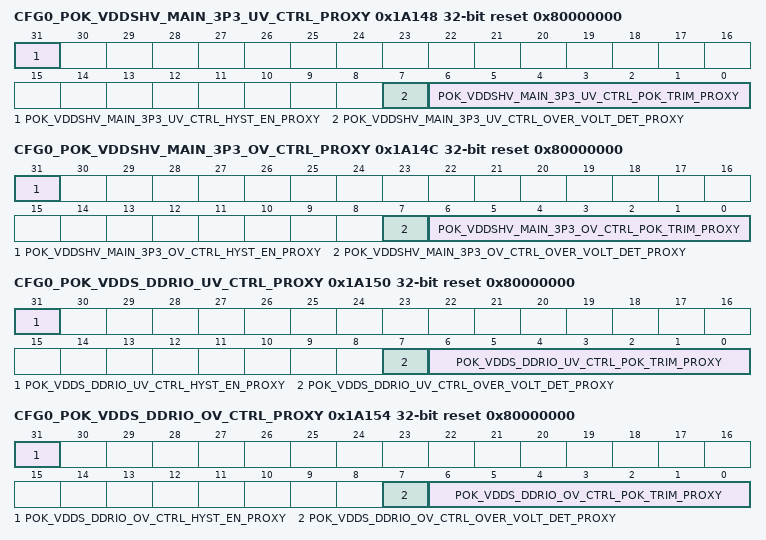
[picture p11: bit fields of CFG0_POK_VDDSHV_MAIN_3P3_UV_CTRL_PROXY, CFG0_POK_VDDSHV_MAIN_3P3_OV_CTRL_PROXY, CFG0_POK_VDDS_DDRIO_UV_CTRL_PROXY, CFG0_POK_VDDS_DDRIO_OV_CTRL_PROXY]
0x1A148 CFG0_POK_VDDSHV_MAIN_3P3_UV_CTRL_PROXY reset 0x80000000
  [31] POK_VDDSHV_MAIN_3P3_UV_CTRL_HYST_EN_PROXY — Activate POK hysteresis
  [7] POK_VDDSHV_MAIN_3P3_UV_CTRL_OVER_VOLT_DET_PROXY — Over / under voltage detection mode 0 - Under voltage detection 1 - Over voltage detection
  [6:0] POK_VDDSHV_MAIN_3P3_UV_CTRL_POK_TRIM_PROXY — POK Trim Bits
0x1A14C CFG0_POK_VDDSHV_MAIN_3P3_OV_CTRL_PROXY reset 0x80000000
  [31] POK_VDDSHV_MAIN_3P3_OV_CTRL_HYST_EN_PROXY — Activate POK hysteresis
  [7] POK_VDDSHV_MAIN_3P3_OV_CTRL_OVER_VOLT_DET_PROXY — Over / under voltage detection mode 0 - Under voltage detection 1 - Over voltage detection
  [6:0] POK_VDDSHV_MAIN_3P3_OV_CTRL_POK_TRIM_PROXY — POK Trim Bits
0x1A150 CFG0_POK_VDDS_DDRIO_UV_CTRL_PROXY reset 0x80000000
  [31] POK_VDDS_DDRIO_UV_CTRL_HYST_EN_PROXY — Activate POK hysteresis
  [7] POK_VDDS_DDRIO_UV_CTRL_OVER_VOLT_DET_PROXY — Over / under voltage detection mode 0 - Under voltage detection 1 - Over voltage detection
  [6:0] POK_VDDS_DDRIO_UV_CTRL_POK_TRIM_PROXY — POK Trim Bits
0x1A154 CFG0_POK_VDDS_DDRIO_OV_CTRL_PROXY reset 0x80000000
  [31] POK_VDDS_DDRIO_OV_CTRL_HYST_EN_PROXY — Activate POK hysteresis
  [7] POK_VDDS_DDRIO_OV_CTRL_OVER_VOLT_DET_PROXY — Over / under voltage detection mode 0 - Under voltage detection 1 - Over voltage detection
  [6:0] POK_VDDS_DDRIO_OV_CTRL_POK_TRIM_PROXY — POK Trim Bits
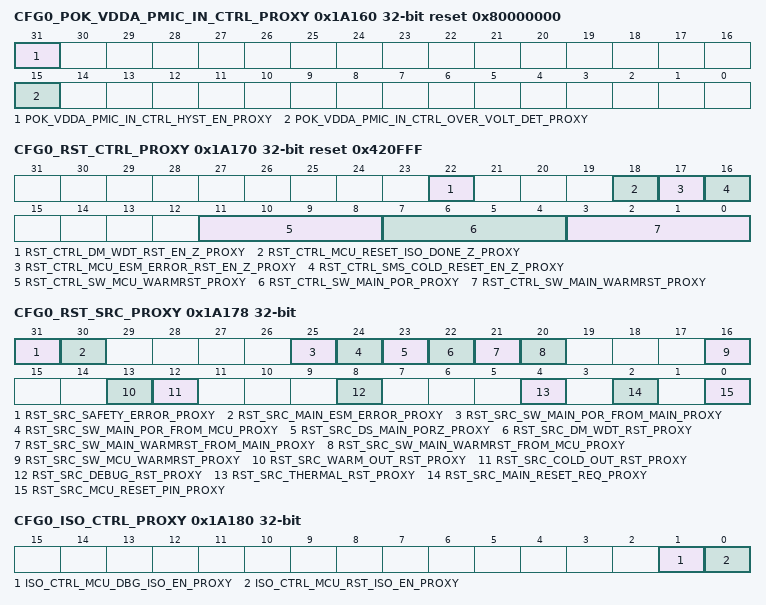
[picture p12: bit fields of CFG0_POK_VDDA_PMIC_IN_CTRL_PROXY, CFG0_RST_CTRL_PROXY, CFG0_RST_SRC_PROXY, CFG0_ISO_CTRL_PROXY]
0x1A160 CFG0_POK_VDDA_PMIC_IN_CTRL_PROXY reset 0x80000000
  [31] POK_VDDA_PMIC_IN_CTRL_HYST_EN_PROXY — Activate POK hysteresis
  [15] POK_VDDA_PMIC_IN_CTRL_OVER_VOLT_DET_PROXY — Over / under voltage detection mode 0 - Under voltage detection 1 - Over voltage detection
0x1A170 CFG0_RST_CTRL_PROXY reset 0x420FFF
  [22] RST_CTRL_DM_WDT_RST_EN_Z_PROXY — Deactivate Reset from DM WDT propogating to MCU domain: 0 - Activated 1 - Deactivated
  [18] RST_CTRL_MCU_RESET_ISO_DONE_Z_PROXY — MCU can set this bit to block warm reset in the main domain which is useful when the MCU may be accessing main domain resources (peripherals, memory..). In this case, the MCU will be notified via an interrupt that there is an outstanding warm reset request for the main domain. Once notified, MCU needs to finish any outstanding operations in has with main domain resources and then clear this bit. After this bit is cleared, the main domain warm reset will unblocked and the warm reset sequence may continue. 0 - Reset of Main Domain is not Blocked by MCU Domain 1 - Reset of Main Domain is Blocked by MCU Domain
  [17] RST_CTRL_MCU_ESM_ERROR_RST_EN_Z_PROXY — Deactivate Reset of MCU by ESM 0 - Activated 1 - Deactivated
  [16] RST_CTRL_SMS_COLD_RESET_EN_Z_PROXY — Deactivate Reset of MCU by SMS 0 - Activated 1 - Deactivated
  [11:8] RST_CTRL_SW_MCU_WARMRST_PROXY — This is a fault tolerant bitfield. Causes MCU Domain Warm Reset when set to 4'b0110, Bits will reset to 4'b1111
  [7:4] RST_CTRL_SW_MAIN_POR_PROXY — This is a fault tolerant bitfield. Causes MAIN Domain Power On Reset when set to 4'b0110, Bits will reset to 4'b1111
  [3:0] RST_CTRL_SW_MAIN_WARMRST_PROXY — This is a fault tolerant bitfield. Causes MAIN Domain Warm Reset when set to 4'b0110, Bits will reset to 4'b1111
0x1A174 CFG0_RST_STAT_PROXY ro
  [0] RST_STAT_MAIN_RESETSTATZ_PROXY — Status of Main Domain Reset: 0 = Reset Asserted 1 = Reset Deasserted
0x1A178 CFG0_RST_SRC_PROXY access not given
  [31] RST_SRC_SAFETY_ERROR_PROXY — Reset Caused by MCU ESM Error (access R/W1TC)
  [30] RST_SRC_MAIN_ESM_ERROR_PROXY — Reset Caused by Main ESM Error (access R/W1TC)
  [25] RST_SRC_SW_MAIN_POR_FROM_MAIN_PROXY — Software Main Power On Reset From MAIN CTRL MMR (access R/W1TC)
  [24] RST_SRC_SW_MAIN_POR_FROM_MCU_PROXY — Software Main Power On Reset From MCU CTRL MMR (access R/W1TC)
  [23] RST_SRC_DS_MAIN_PORZ_PROXY — Reset of Main/Wkup Domains while in Deep Sleep, as a result of an MCU Warm Reset (access R/W1TC)
  [22] RST_SRC_DM_WDT_RST_PROXY — Watchdog Initiated Reset (access R/W1TC)
  [21] RST_SRC_SW_MAIN_WARMRST_FROM_MAIN_PROXY — Software Main Warm Reset from MAIN CTRL MMR (access R/W1TC)
  [20] RST_SRC_SW_MAIN_WARMRST_FROM_MCU_PROXY — Software Main Warm Reset From MCU CTRL MMR (access R/W1TC)
  [16] RST_SRC_SW_MCU_WARMRST_PROXY — Software Warm Reset (access R/W1TC)
  [13] RST_SRC_WARM_OUT_RST_PROXY — SMS Warm Reset (access R/W1TC)
  [12] RST_SRC_COLD_OUT_RST_PROXY — SMS Cold Reset (access R/W1TC)
  [8] RST_SRC_DEBUG_RST_PROXY — Debug Subsystem Initiated Reset (access R/W1TC)
  [4] RST_SRC_THERMAL_RST_PROXY — Thermal Reset (access R/W1TC)
  [2] RST_SRC_MAIN_RESET_REQ_PROXY — Main Reset Pin (access R/W1TC)
  [0] RST_SRC_MCU_RESET_PIN_PROXY — Rest Caused by MCU Reset Pin (access R/W1TC)
0x1A17C CFG0_RST_MAGIC_WORD_PROXY
  [31:0] RST_MAGIC_WORD_MCU_MAGIC_WORD_PROXY — After a MCU_PORz reset this bit field resets to 0x00000000. While this bit field remains 0x00000000 any reset from the Main Domain also propagates through the MCU domain. If the application does not require reset isolation of the MCU domain, it shall leave this bit field with a value of 0x00000000. If the application does require reset isolation of the MCU domain after the initial boot, then the MCU R5FSS CPU must write a nonzero value to the magic word. The actual value is left to software and different values may be used to convey information, but in order to isolate the MCU domain from any warm reset sources that triggers main_resetz, the value must be non-zero. If the value is nonzero and a Main domain warm reset that triggers main_resetz occurs in the main domain, the MCU R5FSS will not be reset. The Main domain bootloader must read this value to determine that the MCU R5FSS is already initialized, and has configured reset isolation. The Main domain bootloader then also skips any initialization steps involving bootstrapping the R5FSS (as it is is already running). Note that MCU_PORz reset is never blocked by a nonzero magic word.
0x1A180 CFG0_ISO_CTRL_PROXY
  [1] ISO_CTRL_MCU_DBG_ISO_EN_PROXY — Isolates the MCU domain from Debug Field values (others are reserved): undefined - undefined undefined - undefined 1'b0 - R5FSS is not debug isolated 1'b1 - R5FSS is isolated from debug if RST_MAGIC_WORD is also nonzero
  [0] ISO_CTRL_MCU_RST_ISO_EN_PROXY — Isolates the MCU domain from Warm Reset initiated by Main Field values (others are reserved): undefined - undefined undefined - undefined 1'b0 - R5FSS is not reset isolated 1'b1 - R5FSS is isolated from main warm reset if RST_MAGIC_WORD is also nonzero
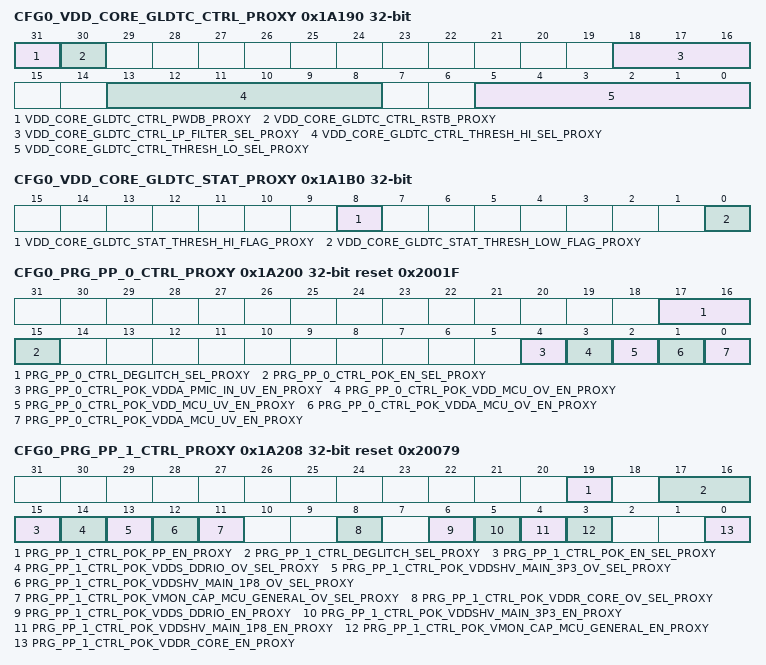
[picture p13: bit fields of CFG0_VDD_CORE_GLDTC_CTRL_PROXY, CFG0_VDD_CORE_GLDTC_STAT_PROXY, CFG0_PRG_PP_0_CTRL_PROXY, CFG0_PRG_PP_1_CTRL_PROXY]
0x1A190 CFG0_VDD_CORE_GLDTC_CTRL_PROXY
  [31] VDD_CORE_GLDTC_CTRL_PWDB_PROXY — Power down - active low. 0 - Deactivate all functions 1 - Activate glitch detectors
  [30] VDD_CORE_GLDTC_CTRL_RSTB_PROXY — Reset - active low. To ensure proper operation, rstb must be not be de-asserted for at least 100 ns after power-up (pwdb de-asserted). Additionally, rstb must be toggled low at least 200 ns after any change in threshold or low-pass filter settings to prevent abnormal trigger events. 0 - Reset glitch detector flags 1 - Glitch detection flags are activated
  [18:16] VDD_CORE_GLDTC_CTRL_LP_FILTER_SEL_PROXY — Selects the glitch detect low-pass filter bandwidth Field values (others are reserved): 3'b000 - 150 kHz 3'b001 - 125 kHz 3'b010 - 100 kHz 3'b011 - 80 kHz 3'b100 - 60 kHz 3'b101 - 45 kHz 3'b110 - 30 kHz 3'b111 - 15 kHz
  [13:8] VDD_CORE_GLDTC_CTRL_THRESH_HI_SEL_PROXY — Selects the high voltage glitch threshold as a percentage of the monitored voltage Field values (others are reserved): 6'b000000 - 93.5% of VDD 6'b000001 - 94.0% of VDD 6'b000010 - 94.5% of VDD 6'b000011 - 95.0% of VDD 6'b000100 - 95.5% of VDD 6'b000101 - 96.0% of VDD 6'b000110 - 96.5% of VDD 6'b000111 - 97.0% of VDD 6'b001000 - 97.5% of VDD 6'b001001 - 98.0% of VDD 6'b001010 - 98.5% of VDD 6'b001011 - 99.0% of VDD 6'b001100 - 99.5% of VDD 6'b001101 - 100.0% of VDD 6'b001110 - 100.5% of VDD 6'b001111 - 101.0% of VDD 6'b010000 - 101.5% of VDD 6'b010001 - 102.0% of VDD 6'b010010 - 102.5% of VDD 6'b010011 - 103.0% of VDD 6'b010100 - 103.5% of VDD 6'b010101 - 104.0% of VDD 6'b010110 - 104.5% of VDD 6'b010111 - 105.0% of VDD 6'b011000 - 105.5% of VDD 6'b011001 - 106.0% of VDD 6'b011010 - 106.5% of VDD 6'b011011 - 107.0% of VDD 6'b011100 - 107.5% of VDD 6'b011101 - 108.0% of VDD 6'b011110 - 108.5% of VDD 6'b011111 - 109.0% of VDD 6'b100000 - 109.5% of VDD 6'b100001 - 110.0% of VDD 6'b100010 - 111.0% of VDD 6'b100011 - 112.0% of VDD 6'b100100 - 113.0% of VDD 6'b100101 - 114.0% of VDD 6'b100110 - 115.0% of VDD 6'b100111 - 116.0% of VDD 6'b101000 - 117.0% of VDD 6'b101001 - 118.0% of VDD 6'b101010 - 119.0% of VDD 6'b101011 - 120.0% of VDD 6'b101100 - 121.0% of VDD 6'b101101 - 122.0% of VDD 6'b101110 - 123.0% of VDD 6'b101111 - 124.0% of VDD 6'b110000 - 125.0% of VDD 6'b110001 - 126.0% of VDD 6'b110010 - 127.0% of VDD 6'b110011 - 128.0% of VDD 6'b110100 - 129.0% of VDD 6'b110101 - 130.0% of VDD 6'b110110 - 131.0% of VDD 6'b110111 - 132.0% of VDD 6'b111000 - 133.0% of VDD 6'b111001 - 134.0% of VDD 6'b111010 - 135.0% of VDD 6'b111011 - 136.0% of VDD 6'b111100 - 137.0% of VDD 6'b111101 - 138.0% of VDD 6'b111110 - 139.0% of VDD 6'b111111 - 140.0% of VDD
  [5:0] VDD_CORE_GLDTC_CTRL_THRESH_LO_SEL_PROXY — Selects the low voltage glitch threshold as a percentage of the monitored voltage Field values (others are reserved): 6'b000000 - 106.5% of VDD 6'b000001 - 106.0% of VDD 6'b000010 - 105.5% of VDD 6'b000011 - 105.0% of VDD 6'b000100 - 104.5% of VDD 6'b000101 - 104.0% of VDD 6'b000110 - 103.5% of VDD 6'b000111 - 103.0% of VDD 6'b001000 - 102.5% of VDD 6'b001001 - 102.0% of VDD 6'b001010 - 101.5% of VDD 6'b001011 - 101.0% of VDD 6'b001100 - 100.5% of VDD 6'b001101 - 100.0% of VDD 6'b001110 - 99.5% of VDD 6'b001111 - 99.0% of VDD 6'b010000 - 98.5% of VDD 6'b010001 - 98.0% of VDD 6'b010010 - 97.5% of VDD 6'b010011 - 97.0% of VDD 6'b010100 - 96.5% of VDD 6'b010101 - 96.0% of VDD 6'b010110 - 95.5% of VDD 6'b010111 - 95.0% of VDD 6'b011000 - 94.5% of VDD 6'b011001 - 94.0% of VDD 6'b011010 - 93.5% of VDD 6'b011011 - 93.0% of VDD 6'b011100 - 92.5% of VDD 6'b011101 - 92.0% of VDD 6'b011110 - 91.5% of VDD 6'b011111 - 91.0% of VDD 6'b100000 - 90.5% of VDD 6'b100001 - 90.0% of VDD 6'b100010 - 89.0% of VDD 6'b100011 - 88.0% of VDD 6'b100100 - 87.0% of VDD 6'b100101 - 86.0% of VDD 6'b100110 - 85.0% of VDD 6'b100111 - 84.0% of VDD 6'b101000 - 83.0% of VDD 6'b101001 - 82.0% of VDD 6'b101010 - 81.0% of VDD 6'b101011 - 80.0% of VDD 6'b101100 - 79.0% of VDD 6'b101101 - 78.0% of VDD 6'b101110 - 77.0% of VDD 6'b101111 - 76.0% of VDD 6'b110000 - 75.0% of VDD 6'b110001 - 74.0% of VDD 6'b110010 - 73.0% of VDD 6'b110011 - 72.0% of VDD 6'b110100 - 71.0% of VDD 6'b110101 - 70.0% of VDD 6'b110110 - 69.0% of VDD 6'b110111 - 68.0% of VDD 6'b111000 - 67.0% of VDD 6'b111001 - 66.0% of VDD 6'b111010 - 65.0% of VDD 6'b111011 - 64.0% of VDD 6'b111100 - 63.0% of VDD 6'b111101 - 62.0% of VDD 6'b111110 - 61.0% of VDD 6'b111111 - 60.0% of VDD
0x1A1B0 CFG0_VDD_CORE_GLDTC_STAT_PROXY ro
  [8] VDD_CORE_GLDTC_STAT_THRESH_HI_FLAG_PROXY — High voltage flag. This flag is cleared by clearing the VDD_CORE_GLDTC_CTRL_rstb bit. 0 - No high voltage detected 1 - Voltage above the high voltage threshold was detected.
  [0] VDD_CORE_GLDTC_STAT_THRESH_LOW_FLAG_PROXY — Low voltage flag. This flag is cleared by clearing the VDD_CORE_GLDTC_CTRL_rstb bit. 0 - No low voltage detected 1 - Voltage below the low voltage threshold was detected.
0x1A200 CFG0_PRG_PP_0_CTRL_PROXY reset 0x2001F
  [17:16] PRG_PP_0_CTRL_DEGLITCH_SEL_PROXY — Deglitch period for PRG_PP0 POKs: 2'b00 - 5 us 2'b01 -10 us 2'b10 - 15 us 2'b11 - 20us
  [15] PRG_PP_0_CTRL_POK_EN_SEL_PROXY — Select POK activate source 0 - POK activates come from hardware tie-offs 1 - POK activates come from PRG_PP0_CTRL register
  [4] PRG_PP_0_CTRL_POK_VDDA_PMIC_IN_UV_EN_PROXY — Activate VDDA_PMIC_IN undervoltage POK detection 0 - POK detection deactivated 1 - POK detection activated
  [3] PRG_PP_0_CTRL_POK_VDD_MCU_OV_EN_PROXY — Activate VDD_MCU overvoltage POK detection 0 - POK detection deactivated 1 - POK detection activated
  [2] PRG_PP_0_CTRL_POK_VDD_MCU_UV_EN_PROXY — Activate VDD_MCU undervoltage POK detection 0 - POK detection deactivated 1 - POK detection activated
  [1] PRG_PP_0_CTRL_POK_VDDA_MCU_OV_EN_PROXY — Activate 1.8V VDDA_MCU overvoltage POK detection 0 - POK detection deactivated 1 - POK detection activated
  [0] PRG_PP_0_CTRL_POK_VDDA_MCU_UV_EN_PROXY — Activate 1.8V VDDA_MCU undervoltage POK detection 0 - POK detection deactivated 1 - POK detection activated
0x1A208 CFG0_PRG_PP_1_CTRL_PROXY reset 0x20079
  [19] PRG_PP_1_CTRL_POK_PP_EN_PROXY — POK ping-pong activate. When set, activatesautomatic switching between undervoltage andovervoltage detection on PRG_PP1 (POK_VDDR_CORE, POK_VDDSHV_MCU_1P8, POK_VDDSHV_MCU_3P3, POK_VMON_CAP_MCU_GENERAL, POK_VDDSHV_MAIN_1P8, POK_VDDSHV_MAIN_3P3, and POK_VDDS_DDRIO) POKs. This bit has no effect if the POK's ov_sel bit = 1. 0 - No pingpong operation. UV/OV operationselected by each POK ov_sel bit 1 - Pingpong operation activated .
  [17:16] PRG_PP_1_CTRL_DEGLITCH_SEL_PROXY — Deglitch period for PRG_PP1 POKs: 2'b00 - 5 us 2'b01 -10 us 2'b10 - 15 us 2'b11 - 20us
  [15] PRG_PP_1_CTRL_POK_EN_SEL_PROXY — Select POK activate source 0 - POK activates come from hardware tie-offs 1 - POK activates come from PRG_PP1_CTRL register
  [14] PRG_PP_1_CTRL_POK_VDDS_DDRIO_OV_SEL_PROXY — POK_VDDS_DDRIO mode: 0 = Undervoltage (pok_pp_en = 0) Ping-Pong (pok_pp_en = 1) 1 = Overvoltage (pok_pp_en = x)
  [13] PRG_PP_1_CTRL_POK_VDDSHV_MAIN_3P3_OV_SEL_PROXY — POK_VDDSHV_MAIN_3P3 mode: 0 = Undervoltage (pok_pp_en = 0) Ping-Pong (pok_pp_en = 1) 1 = Overvoltage (pok_pp_en = x)
  [12] PRG_PP_1_CTRL_POK_VDDSHV_MAIN_1P8_OV_SEL_PROXY — POK_VDDSHV_MAIN_1P8 mode: 0 = Undervoltage (pok_pp_en = 0) Ping-Pong (pok_pp_en = 1) 1 = Overvoltage (pok_pp_en = x)
  [11] PRG_PP_1_CTRL_POK_VMON_CAP_MCU_GENERAL_OV_SEL_PROXY — POK_VMON_CAP_MCU_GENERAL mode: 0 = Undervoltage (pok_pp_en = 0) Ping-Pong (pok_pp_en = 1) 1 = Overvoltage (pok_pp_en = x)
  [8] PRG_PP_1_CTRL_POK_VDDR_CORE_OV_SEL_PROXY — POK_VDDR_CORE Mode: 0 = Undervoltage (pok_pp_en = 0) Ping-Pong (pok_pp_en = 1) 1 = Overvoltage (pok_pp_en = x)
  [6] PRG_PP_1_CTRL_POK_VDDS_DDRIO_EN_PROXY — Activate POK_VDDS_DDRIO (if pok_en_sel = 1): 0 = POK Detection Deactivated 1 = POK Detection Activated
  [5] PRG_PP_1_CTRL_POK_VDDSHV_MAIN_3P3_EN_PROXY — Activate POK_VDDSHV_MAIN_3P3 (if pok_en_sel = 1): 0 = POK Detection Deactivated 1 = POK Detection Activated
  [4] PRG_PP_1_CTRL_POK_VDDSHV_MAIN_1P8_EN_PROXY — Activate POK_VDDSHV_MAIN_1P8 (if pok_en_sel = 1): 0 = POK Detection Deactivated 1 = POK Detection Activated
  [3] PRG_PP_1_CTRL_POK_VMON_CAP_MCU_GENERAL_EN_PROXY — Activate POK_VMON_CAP_MCU_GENERAL (if pok_en_sel = 1): 0 = POK Detection Deactivated 1 = POK Detection Activated
  [0] PRG_PP_1_CTRL_POK_VDDR_CORE_EN_PROXY — Activate POK_VDDR_CORE (if pok_en_sel = 1): 0 = POK Detection Deactivated 1 = POK Detection Activated
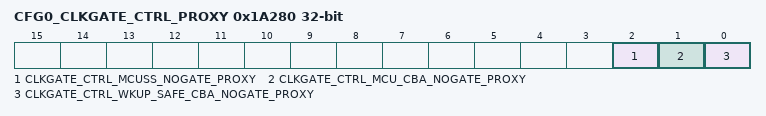
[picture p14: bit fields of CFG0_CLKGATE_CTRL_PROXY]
0x1A280 CFG0_CLKGATE_CTRL_PROXY
  [2] CLKGATE_CTRL_MCUSS_NOGATE_PROXY — MCU Subsystem clock gate deactivate. 0 - Clocks are gated on idle for power savings 1 - Clocks are not gated on idle, power saving deactivated
  [1] CLKGATE_CTRL_MCU_CBA_NOGATE_PROXY — MCU domain Data bus (mcu_cbass) clock gate deactivate. 0 - Clocks are gated on idle for power savings 1 - Clocks are not gated on idle, power saving deactivated
  [0] CLKGATE_CTRL_WKUP_SAFE_CBA_NOGATE_PROXY — WKUP domain Infrastructure bus (wkup_safe_cbass) clock gate deactivate. 0 - Clocks are gated on idle for power savings 1 - Clocks are not gated on idle, power saving deactivated
0x1B008 CFG0_LOCK6_KICK0_PROXY
  [31:0] LOCK6_KICK0_PROXY — - KICK0 component
0x1B00C CFG0_LOCK6_KICK1_PROXY
  [31:0] LOCK6_KICK1_PROXY — - KICK1 component
{0x1B100+4i} CFG0_CLAIMREG_P6_R{i} (i=0..5)
  [31:0] CLAIMREG_P6_R{i} — Claim bits for Partition 6
